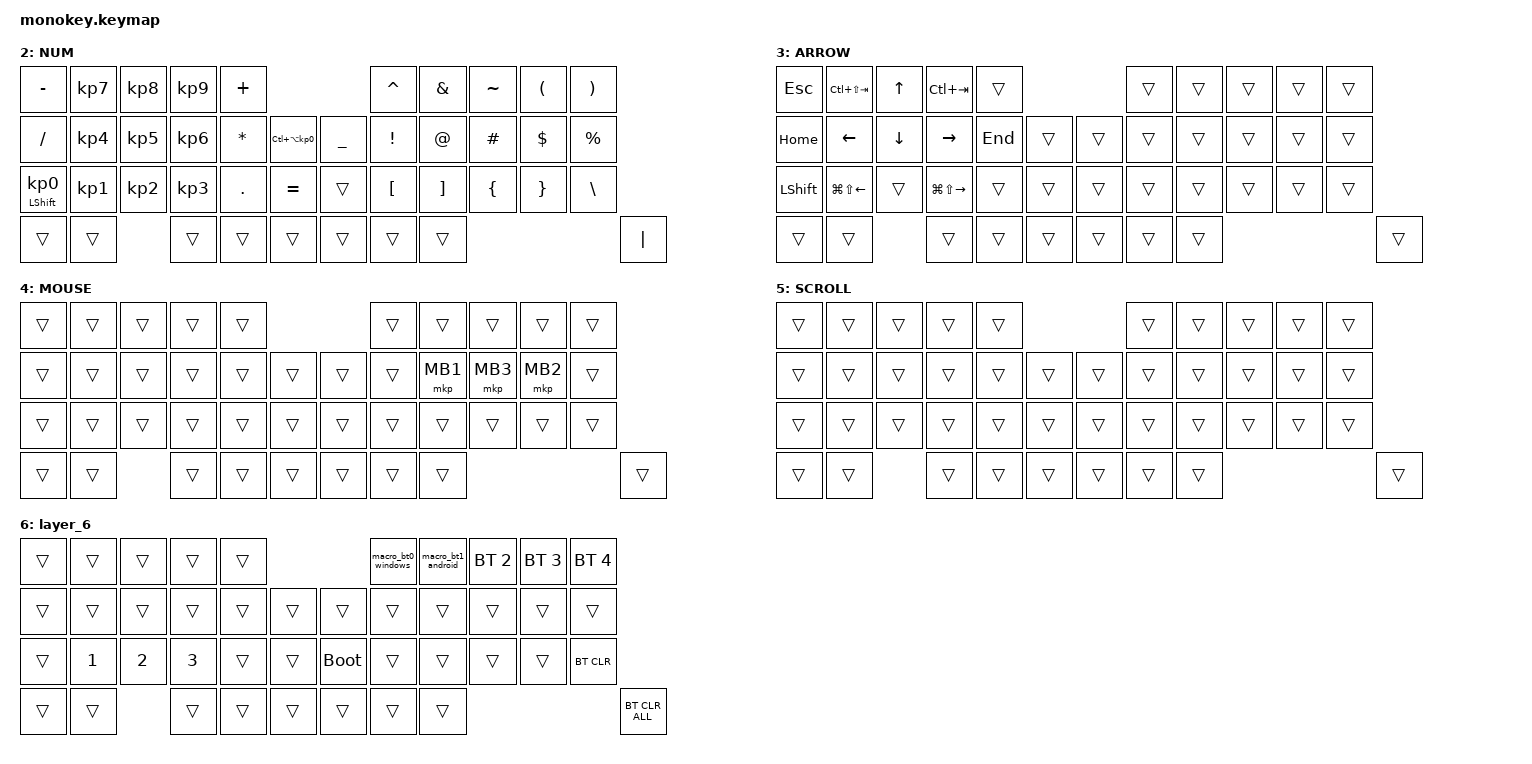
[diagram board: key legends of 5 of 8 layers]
#include <behaviors.dtsi>
#include <dt-bindings/zmk/bt.h>
#include <dt-bindings/zmk/keys.h>
#include <dt-bindings/zmk/mouse.h>

#define MOUSE 4
#define SCROLL 5
#define NUM 6
#define ANDROID_DEFAULT 7

&mt {
    flavor = "balanced";
    quick-tap-ms = <0>;
};

/ {
    combos {
        compatible = "zmk,combos";

        tab {
            bindings = <&kp TAB>;
            key-positions = <11 12>;
        };

        shift_tab {
            bindings = <&kp LS(TAB)>;
            key-positions = <12 13>;
        };

        muhennkann {
            bindings = <&macro_muhenkan_to_0>;
            key-positions = <11 10>;
        };

        double_quotation {
            bindings = <&kp DQT>;
            key-positions = <20 21>;
        };

    };

    macros {
        macro_muhenkan_to_0: macro_muhenkan_to_0 {
            compatible = "zmk,behavior-macro";
            #binding-cells = <0>;
            bindings = <&to 0 &kp INT_MUHENKAN>;
            label = "MACRO_MUHENKAN_TO_0";
        };

         macro_repeated_backspace: macro_repeated_backspace {
            compatible = "zmk,behavior-macro";
            label = "MACRO_REPEATED_BACKSPACE";
            #binding-cells = <0>;

            bindings = <
                &kp BACKSPACE
            >;
        };

        macro_bt0_windows: macro_bt0_windows {
            compatible = "zmk,behavior-macro";
            label = "BT0_WINDOWS";
            #binding-cells = <0>;
            bindings = <&bt BT_SEL 0 &to 0>;
        };

        macro_bt1_android: macro_bt1_android {
            compatible = "zmk,behavior-macro";
            label = "BT1_ANDROID";
            #binding-cells = <0>;
            bindings = <&bt BT_SEL 1 &to 7>;
        };
    };


     tap_dance {
        compatible = "zmk,tap-dance";

        td_backspace {
            label = "TD_BACKSPACE";
            #binding-cells = <0>;
            // 1回タップ、2回タップを定義
            taps = <1>, <2>;

            // 1回タップ => &kp BACKSPACE
            // 2回タップ => マクロを呼び出し連打
            bindings = <
                &kp BACKSPACE
                &macro_repeated_backspace
            >;
        };
    };

    behaviors {
        right_click: right_click_behavior {
            compatible = "zmk,behavior-mouse-key";
            label = "RIGHT_CLICK";
            #binding-cells = <0>;
            // 右クリックは通常 MB2 に対応（ZMKの標準定義）
            bindings = <&mkp MB2>;
        };

         backspace_hold_layer: backspace_hold_layer {
            compatible = "zmk,behavior-hold-tap";
            label = "BACKSPACE_HOLD_LAYER";
            #binding-cells = <0>;

            // [タップ動作]       [ホールド動作]
            bindings = < &td_backspace >, < &mo 3 >;

            // ホールド判定の時間（例：200ms）
            tapping-term-ms = <200>;
        };
    };

    keymap {
        compatible = "zmk,keymap";

        default_layer {
          bindings = <
&kp Q      &kp W           &kp E         &kp R             &kp T                                &kp Y          &kp U                &kp I     &kp O     &kp P
&kp A      &kp S           &kp D         &kp F             &kp G                                &kp H          &kp J                &kp K     &kp L     &kp ENTER
&kp Z      &kp X           &kp C         &kp V             &kp B                                &kp N          &kp M                &mkp MB1  &mkp MB2  &kp SLASH
&kp LCTRL  &kp LEFT_SHIFT  &kp LEFT_ALT  &kp LEFT_COMMAND  &lt 1 SPACE  &lt 2 TAB    &kp BACKSPACE  &lt 3 RIGHT_COMMAND            &kp ESC   &kp ESC
            >;

            sensor-bindings = <&inc_dec_kp PG_UP PAGE_DOWN>;
        };

        FUNCTION {
            bindings = <
&trans  &trans  &trans  &trans  &trans                    &trans  &trans  &trans  &trans  &trans
&trans  &trans  &trans  &trans  &trans     &trans    &kp MINUS  &kp EQUAL  &kp LBKT  &kp SQT  &kp SEMI  &trans
&trans  &trans  &trans  &trans  &trans     &trans    &trans     &kp F1     &trans    &trans   &kp F26   &trans
&mo 7   &trans  &trans  &trans  &trans     &trans    &trans     &kp DEL    &trans    &trans
            >;
        };

        NUM {
            bindings = <
&kp MINUS                   &kp KP_N7  &kp KP_N8  &kp KP_N9  &kp PLUS                                                 &kp CARET         &kp AMPERSAND      &kp TILDE       &kp LEFT_PARENTHESIS  &kp RIGHT_PARENTHESIS
&kp SLASH                   &kp KP_N4  &kp KP_N5  &kp KP_N6  &kp ASTERISK  &kp LC(LA(KP_N0))    &kp UNDERSCORE  &kp EXCLAMATION   &kp AT_SIGN        &kp HASH        &kp DOLLAR            &kp PERCENT
&mt LEFT_SHIFT KP_N0  &kp KP_N1  &kp KP_N2  &kp KP_N3  &kp PERIOD    &kp EQUAL                  &trans          &kp LEFT_BRACKET  &kp RIGHT_BRACKET  &kp LEFT_BRACE  &kp RIGHT_BRACE       &kp BACKSLASH
&trans                      &trans           &trans           &trans           &trans        &trans                     &trans          &trans                                                                     &kp PIPE
            >;
        };

        ARROW {
            bindings = <
&kp ESCAPE      &kp LC(LS(TAB))         &kp UP_ARROW    &kp LC(TAB)              &trans                     &trans  &trans  &trans  &trans  &trans
&kp HOME        &kp LEFT_ARROW          &kp DOWN_ARROW  &kp RIGHT_ARROW          &kp END  &trans    &trans  &trans  &trans  &trans  &trans  &trans
&kp LEFT_SHIFT  &kp LG(LS(LEFT_ARROW))  &trans          &kp LG(LS(RIGHT_ARROW))  &trans   &trans    &trans  &trans  &trans  &trans  &trans  &trans
&trans          &trans                  &trans          &trans                   &trans   &trans    &trans  &trans                          &trans
            >;

            sensor-bindings = <&inc_dec_kp LC(PAGE_UP) LC(PAGE_DOWN)>;
        };

        MOUSE {
            bindings = <
&trans  &trans  &trans  &trans  &trans                    &trans  &trans    &trans    &trans    &trans
&trans  &trans  &trans  &trans  &trans  &trans    &trans  &trans  &mkp MB1  &mkp MB3  &mkp MB2  &trans
&trans  &trans  &trans  &trans  &trans  &trans    &trans  &trans  &trans    &trans    &trans    &trans
&trans  &trans  &trans  &trans  &trans  &trans    &trans  &trans                                &trans
            >;
        };

        SCROLL {
            bindings = <
&trans  &trans  &trans  &trans  &trans                    &trans  &trans  &trans  &trans  &trans
&trans  &trans  &trans  &trans  &trans  &trans    &trans  &trans  &trans  &trans  &trans  &trans
&trans  &trans  &trans  &trans  &trans  &trans    &trans  &trans  &trans  &trans  &trans  &trans
&trans  &trans  &trans  &trans  &trans  &trans    &trans  &trans                          &trans
            >;
        };

        layer_6 {
            bindings = <
&trans  &trans        &trans        &trans        &trans                         &macro_bt0_windows  &macro_bt1_android  &bt BT_SEL 2  &bt BT_SEL 3  &bt BT_SEL 4
&trans  &trans        &trans        &trans        &trans  &trans    &trans              &trans              &trans        &trans        &trans        &trans
&trans  &kp NUMBER_1  &kp NUMBER_2  &kp NUMBER_3  &trans  &trans    &bootloader         &trans              &trans        &trans        &trans        &bt BT_CLR
&trans  &trans        &trans        &trans        &trans  &trans    &trans              &trans                                                        &bt BT_CLR_ALL
            >;
        };

        default_android {
            bindings = <
&kp Q      &kp W           &kp E         &kp R             &kp T                                &kp Y          &kp U                &kp I     &kp O     &kp P
&kp A      &kp S           &kp D         &kp F             &kp G                                &kp H          &kp J                &kp K     &kp L     &kp ENTER
&kp Z      &kp X           &kp C         &kp V             &kp B                                &kp N          &kp M                &mkp MB1  &mkp MB2  &kp SLASH
&kp LCTRL  &kp LEFT_SHIFT  &kp LEFT_ALT  &kp LEFT_CTRL     &lt 1 SPACE  &lt 2 TAB    &kp BACKSPACE  &lt 3 RIGHT_CTRL            &kp ESC   &kp ESC
            >;

            sensor-bindings = <&inc_dec_kp PG_UP PAGE_DOWN>;
        };
    };
};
